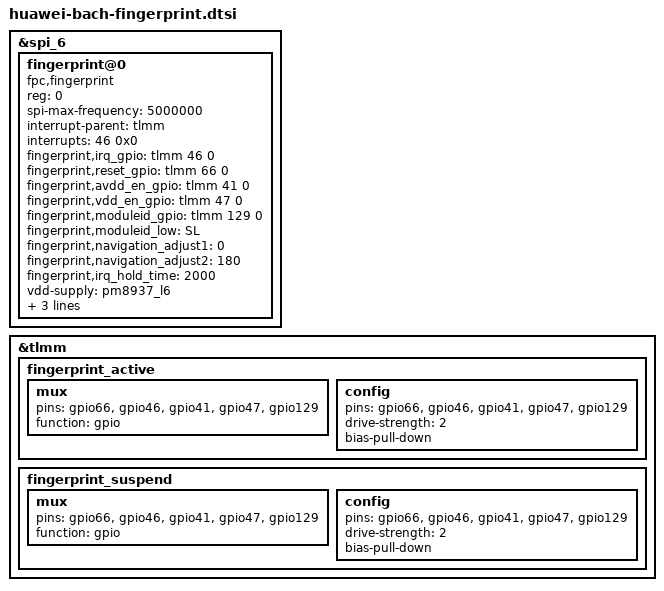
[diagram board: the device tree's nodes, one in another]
/*
 * Huawei BAH-W09 fingerprint — FPC1020 (SPI child of SPI6)
 *
 * Ported from 3.18 kernel (huawei-fingerprint.dtsi).
 * GPIO assignments match 3.18 DTS:
 *   GPIO 41 = avdd_en (power enable)
 *   GPIO 46 = IRQ
 *   GPIO 47 = vdd_en (power enable)
 *   GPIO 66 = reset
 *   GPIO 129 = module ID
 */

&spi_6 {
	status = "okay";

	fingerprint@0 {
		compatible = "fpc,fingerprint";
		reg = <0>;
		spi-max-frequency = <5000000>;
		interrupt-parent = <&tlmm>;
		interrupts = <46 0x0>;
		fingerprint,irq_gpio = <&tlmm 46 0>;
		fingerprint,reset_gpio = <&tlmm 66 0>;
		fingerprint,avdd_en_gpio = <&tlmm 41 0>;
		fingerprint,vdd_en_gpio = <&tlmm 47 0>;
		fingerprint,moduleid_gpio = <&tlmm 129 0>;
		fingerprint,moduleid_low = "SL";
		fingerprint,navigation_adjust1 = <0>;
		fingerprint,navigation_adjust2 = <180>;
		fingerprint,irq_hold_time = <2000>;
		vdd-supply = <&pm8937_l6>;
		fingerprint,vdd = "vdd";
		pinctrl-names = "default", "idle";
		pinctrl-0 = <&fingerprint_active>;
		pinctrl-1 = <&fingerprint_suspend>;
		status = "okay";
	};
};

&tlmm {
	fingerprint_active: fingerprint_active {
		mux {
			pins = "gpio66", "gpio46", "gpio41", "gpio47", "gpio129";
			function = "gpio";
		};
		config {
			pins = "gpio66", "gpio46", "gpio41", "gpio47", "gpio129";
			drive-strength = <2>;
			bias-pull-down;
		};
	};

	fingerprint_suspend: fingerprint_suspend {
		mux {
			pins = "gpio66", "gpio46", "gpio41", "gpio47", "gpio129";
			function = "gpio";
		};
		config {
			pins = "gpio66", "gpio46", "gpio41", "gpio47", "gpio129";
			drive-strength = <2>;
			bias-pull-down;
		};
	};
};
